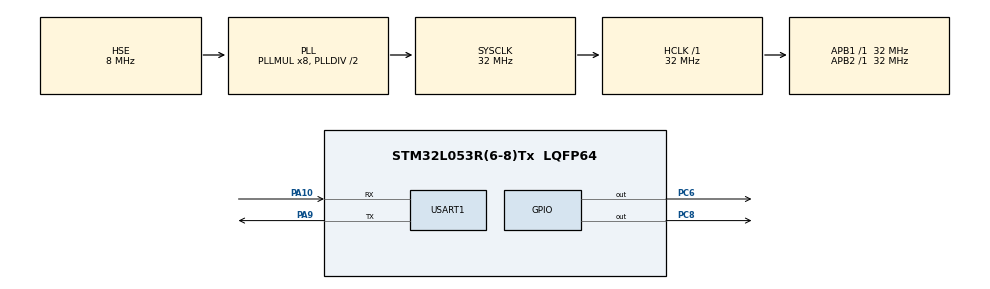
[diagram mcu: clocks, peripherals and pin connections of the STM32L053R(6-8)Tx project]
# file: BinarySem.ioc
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FREERTOS.BinarySemaphores01=myBinarySem01,Dynamic,NULL
FREERTOS.Tasks01=Periodic,0,128,PeriodicTask,Default,NULL,Dynamic,NULL,NULL;Handle,-3,128,HandleTask,Default,NULL,Dynamic,NULL,NULL
Mcu.Family=STM32L0
Mcu.Name=STM32L053R(6-8)Tx
Mcu.Package=LQFP64
NVIC.TIM2_IRQn=true\:0\:0\:false\:false\:true\:false\:false\:true
NVIC.TimeBase=TIM2_IRQn
NVIC.TimeBaseIP=TIM2
PA10.Mode=Asynchronous
PA10.Signal=USART1_RX
PA13.Mode=Serial_Wire
PA13.Signal=SYS_SWDIO
PA14.Mode=Serial_Wire
PA14.Signal=SYS_SWCLK
PA9.Mode=Asynchronous
PA9.Signal=USART1_TX
PC6.Signal=GPIO_Output
PC8.Signal=GPIO_Output
PH0-OSC_IN.Mode=HSE-External-Oscillator
PH0-OSC_IN.Signal=RCC_OSC_IN
PH1-OSC_OUT.Mode=HSE-External-Oscillator
PH1-OSC_OUT.Signal=RCC_OSC_OUT
ProjectManager.HeapSize=0x200
ProjectManager.StackSize=0x400
ProjectManager.TargetToolchain=MDK-ARM V5.27
RCC.AHBFreq_Value=32000000
RCC.APB1Freq_Value=32000000
RCC.APB1TimFreq_Value=32000000
RCC.APB2Freq_Value=32000000
RCC.APB2TimFreq_Value=32000000
RCC.HCLKFreq_Value=32000000
RCC.HSE_VALUE=8000000
RCC.HSI16_VALUE=16000000
RCC.HSI48_VALUE=48000000
RCC.HSI_VALUE=16000000
RCC.LSE_VALUE=32768
RCC.MSI_VALUE=2097000
RCC.PLLMUL=RCC_PLLMUL_8
RCC.PLLSourceVirtual=RCC_PLLSOURCE_HSE
RCC.SYSCLKFreq_VALUE=32000000
RCC.SYSCLKSource=RCC_SYSCLKSOURCE_PLLCLK
RCC.VCOOutputFreq_Value=64000000
USART1.VirtualMode-Asynchronous=VM_ASYNC
VP_FREERTOS_VS_CMSIS_V1.Mode=CMSIS_V1
VP_SYS_VS_tim2.Mode=TIM2
board=custom

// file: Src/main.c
/* USER CODE BEGIN Header */
/**
  ******************************************************************************
  * @file           : main.c
  * @brief          : Main program body
  ******************************************************************************
  * @attention
  *
  * <h2><center>&copy; Copyright (c) 2020 STMicroelectronics.
  * All rights reserved.</center></h2>
  *
  * This software component is licensed by ST under Ultimate Liberty license
  * SLA0044, the "License"; You may not use this file except in compliance with
  * the License. You may obtain a copy of the License at:
  *                             www.st.com/SLA0044
  *
  ******************************************************************************
  */
/* USER CODE END Header */

#include "main.h"
#include "cmsis_os.h"
#include "usart.h"
#include "gpio.h"

void SystemClock_Config(void);
void MX_FREERTOS_Init(void);

int main(void)
{

  /* MCU Configuration--------------------------------------------------------*/

  /* Reset of all peripherals, Initializes the Flash interface and the Systick. */
  HAL_Init();

  /* Configure the system clock */
  SystemClock_Config();

  /* Initialize all configured peripherals */
  MX_GPIO_Init();
  MX_USART1_UART_Init();

  /* Call init function for freertos objects (in freertos.c) */
  MX_FREERTOS_Init();
  /* Start scheduler */
  osKernelStart();

  /* We should never get here as control is now taken by the scheduler */
  /* Infinite loop */
  while (1)
  {

  }
}

void SystemClock_Config(void)
{
  RCC_OscInitTypeDef RCC_OscInitStruct = {0};
  RCC_ClkInitTypeDef RCC_ClkInitStruct = {0};
  RCC_PeriphCLKInitTypeDef PeriphClkInit = {0};

  /** Configure the main internal regulator output voltage
  */
  __HAL_PWR_VOLTAGESCALING_CONFIG(PWR_REGULATOR_VOLTAGE_SCALE1);
  /** Initializes the CPU, AHB and APB busses clocks
  */
  RCC_OscInitStruct.OscillatorType = RCC_OSCILLATORTYPE_HSE;
  RCC_OscInitStruct.HSEState = RCC_HSE_ON;
  RCC_OscInitStruct.PLL.PLLState = RCC_PLL_ON;
  RCC_OscInitStruct.PLL.PLLSource = RCC_PLLSOURCE_HSE;
  RCC_OscInitStruct.PLL.PLLMUL = RCC_PLLMUL_8;
  RCC_OscInitStruct.PLL.PLLDIV = RCC_PLLDIV_2;
  if (HAL_RCC_OscConfig(&RCC_OscInitStruct) != HAL_OK)
  {
    Error_Handler();
  }
  /** Initializes the CPU, AHB and APB busses clocks
  */
  RCC_ClkInitStruct.ClockType = RCC_CLOCKTYPE_HCLK|RCC_CLOCKTYPE_SYSCLK
                              |RCC_CLOCKTYPE_PCLK1|RCC_CLOCKTYPE_PCLK2;
  RCC_ClkInitStruct.SYSCLKSource = RCC_SYSCLKSOURCE_PLLCLK;
  RCC_ClkInitStruct.AHBCLKDivider = RCC_SYSCLK_DIV1;
  RCC_ClkInitStruct.APB1CLKDivider = RCC_HCLK_DIV1;
  RCC_ClkInitStruct.APB2CLKDivider = RCC_HCLK_DIV1;

  if (HAL_RCC_ClockConfig(&RCC_ClkInitStruct, FLASH_LATENCY_1) != HAL_OK)
  {
    Error_Handler();
  }
  PeriphClkInit.PeriphClockSelection = RCC_PERIPHCLK_USART1;
  PeriphClkInit.Usart1ClockSelection = RCC_USART1CLKSOURCE_PCLK2;
  if (HAL_RCCEx_PeriphCLKConfig(&PeriphClkInit) != HAL_OK)
  {
    Error_Handler();
  }
}

 /**
  * @brief  Period elapsed callback in non blocking mode
  * @note   This function is called  when TIM2 interrupt took place, inside
  * HAL_TIM_IRQHandler(). It makes a direct call to HAL_IncTick() to increment
  * a global variable "uwTick" used as application time base.
  * @param  htim : TIM handle
  * @retval None
  */
void HAL_TIM_PeriodElapsedCallback(TIM_HandleTypeDef *htim)
{
  if (htim->Instance == TIM2) {
    HAL_IncTick();
  }
}

void Error_Handler(void)
{
}

/************************ (C) COPYRIGHT STMicroelectronics *****END OF FILE****/

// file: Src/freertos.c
/* USER CODE BEGIN Header */
/**
  ******************************************************************************
  * File Name          : freertos.c
  * Description        : Code for freertos applications
  ******************************************************************************
  * @attention
  *
  * <h2><center>&copy; Copyright (c) 2020 STMicroelectronics.
  * All rights reserved.</center></h2>
  *
  * This software component is licensed by ST under Ultimate Liberty license
  * SLA0044, the "License"; You may not use this file except in compliance with
  * the License. You may obtain a copy of the License at:
  *                             www.st.com/SLA0044
  *
  ******************************************************************************
  */
/* USER CODE END Header */

#include "FreeRTOS.h"
#include "task.h"
#include "main.h"
#include "cmsis_os.h"

osThreadId PeriodicHandle;
osThreadId HandleHandle;
osSemaphoreId myBinarySem01Handle;

void PeriodicTask(void const * argument);
void HandleTask(void const * argument);

void MX_FREERTOS_Init(void); /* (MISRA C 2004 rule 8.1) */

/* GetIdleTaskMemory prototype (linked to static allocation support) */
void vApplicationGetIdleTaskMemory( StaticTask_t **ppxIdleTaskTCBBuffer, StackType_t **ppxIdleTaskStackBuffer, uint32_t *pulIdleTaskStackSize );

/* USER CODE BEGIN GET_IDLE_TASK_MEMORY */
static StaticTask_t xIdleTaskTCBBuffer;
static StackType_t xIdleStack[configMINIMAL_STACK_SIZE];

void vApplicationGetIdleTaskMemory( StaticTask_t **ppxIdleTaskTCBBuffer, StackType_t **ppxIdleTaskStackBuffer, uint32_t *pulIdleTaskStackSize )
{
  *ppxIdleTaskTCBBuffer = &xIdleTaskTCBBuffer;
  *ppxIdleTaskStackBuffer = &xIdleStack[0];
  *pulIdleTaskStackSize = configMINIMAL_STACK_SIZE;
  /* place for user code */
}
/* USER CODE END GET_IDLE_TASK_MEMORY */

void MX_FREERTOS_Init(void) {

  /* Create the semaphores(s) */
  /* definition and creation of myBinarySem01 */
  osSemaphoreDef(myBinarySem01);
  myBinarySem01Handle = osSemaphoreCreate(osSemaphore(myBinarySem01), 1);

  /* Create the thread(s) */
  /* definition and creation of Periodic */
  osThreadDef(Periodic, PeriodicTask, osPriorityNormal, 0, 128);
  PeriodicHandle = osThreadCreate(osThread(Periodic), NULL);

  /* definition and creation of Handle */
  osThreadDef(Handle, HandleTask, osPriorityIdle, 0, 128);
  HandleHandle = osThreadCreate(osThread(Handle), NULL);

}

void PeriodicTask(void const * argument)
{
  /* USER CODE BEGIN PeriodicTask */
  /* Infinite loop */
  for(;;)
  {
	  osDelay(1000);
	  osSemaphoreRelease(myBinarySem01Handle);
  }
  /* USER CODE END PeriodicTask */
}

void HandleTask(void const * argument)
{
  /* USER CODE BEGIN HandleTask */
  /* Infinite loop */
  for(;;)
  {
      osSemaphoreWait(myBinarySem01Handle,osWaitForever);
	  HAL_GPIO_TogglePin(GPIOC,GPIO_PIN_8);
	  HAL_GPIO_TogglePin(GPIOC,GPIO_PIN_6);
  }
  /* USER CODE END HandleTask */
}

/************************ (C) COPYRIGHT STMicroelectronics *****END OF FILE****/
